# AE302F40C1537LE_CM55_HP_View register map
Vendor: Alif Semiconductor; Series: E3; File version: 1.0
CPU: CM55 r1p0, selectable endian, MPU, FPU, double-precision FPU, DSP, VTOR, 8 interrupt priority bits, 1 SAU regions
Registers are 32-bit, read-write, reset 0x0 unless marked. A register's access mark holds for its fields unless they carry their own. Offsets are from the block's base; [hi:lo] are bit positions; 'fields as' and 'values as' point back to an identical list.

## I2C0
Base 0x49010000
Same registers: I2C1 0x49011000, I2C2 0x49012000, I2C3 0x49013000
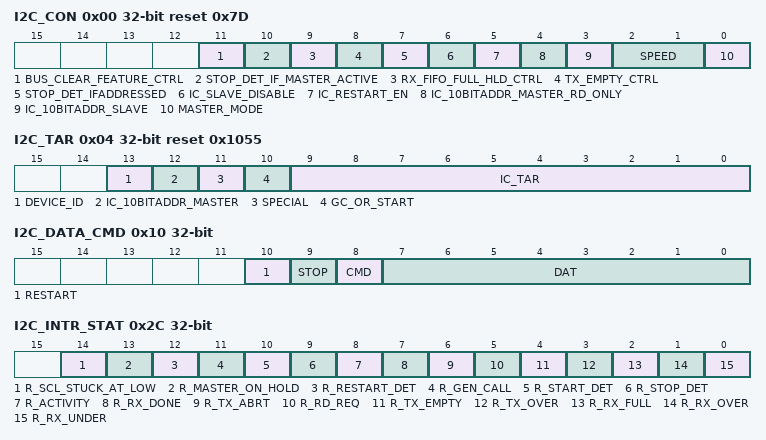
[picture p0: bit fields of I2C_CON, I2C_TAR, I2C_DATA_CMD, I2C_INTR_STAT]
0x00 I2C_CON reset 0x7D — Control Register
  [11] BUS_CLEAR_FEATURE_CTRL — In Master mode: In Slave mode this bit is not applicable.
    0=Bus Clear Feature is disabled; 1=Bus Clear Feature is enabled
  [10] STOP_DET_IF_MASTER_ACTIVE ro — In Master mode:
    0=Master issues the STOP_DET interrupt irrespective of whether master is active or not; 1=Master issues the STOP_DET interrupt only when master is active
  [9] RX_FIFO_FULL_HLD_CTRL ro — This bit controls whether I2C should hold the bus when the Rx FIFO is physically full to its IC_COMP_PARAM_1[RX_BUFFER_DEPTH].
    0=Overflow when RX_FIFO is full; 1=Hold bus when RX_FIFO is full
  [8] TX_EMPTY_CTRL — This bit controls the generation of the TX_EMPTY interrupt, as described in the I2C_RAW_INTR_STAT[TX_EMPTY].
    0=Default behaviour of TX_EMPTY interrupt; 1=Controlled generation of TX_EMPTY interrupt
  [7] STOP_DET_IFADDRESSED — In Slave mode: During a general call address, this slave does not issue the STOP_DET interrupt if STOP_DET_IF_ADDRESSED = 0x1, even if the slave responds to the general call address by generating ACK. The STOP_DET interrupt is generated only when the transmitted address matches the slave address.
    0=Issues the STOP_DET irrespective of whether it is addressed or not; 1=Issues the STOP_DET interrrupt only when it is addressed
  [6] IC_SLAVE_DISABLE — This bit controls whether I2C has its slave disabled. If this bit is set, the Slave mode is disabled, and I2C functions only as a master; it does not perform any action that requires a slave. Software should ensure that if this bit is set to 0, then bit MASTER_MODE should also be set to 0.
    0=Slave mode is enabled; 1=Slave mode is disabled
  [5] IC_RESTART_EN — Determines whether RESTART conditions may be sent when acting as a master. Some older slaves do not support handling RESTART conditions; however, RESTART conditions are used in several I2C operations. When RESTART is disabled, the master is prohibited from performing the following functions: - Sending a START BYTE - Performing any high-speed mode operation - Performing direction changes in combined format mode - Performing a read operation with a 10-bit address
    0=Master restart disabled; 1=Master restart enabled
  [4] IC_10BITADDR_MASTER_RD_ONLY ro — The function of this bit is handled by I2C_TAR[IC_10BITADDR_MASTER] bit, and it is read only.
    0=Master 7-bit addressing mode; 1=Master 10-bit addressing mode
  [3] IC_10BITADDR_SLAVE — When acting as a slave, this bit controls whether the I2C responds to 7-bit or 10-bit addresses. 0x0: 7-bit addressing. The I2C ignores transactions that involve 10-bit addressing; for 7-bit addressing, only the lower 7 bits of the I2C_SAR register are compared. 0x1: 10-bit addressing. The I2C responds to only 10-bit addressing transfers that match the full 10 bits of the I2C_SAR register. 0x0: Slave 7-bit addressing 0x1: Slave 10-bit addressing
  [2:1] SPEED — These bits control at which speed the I2C operates; its setting is relevant only if the I2C operates in Master mode. Hardware protects against illegal values being programmed by software. These bits must be programmed appropriately for Slave mode also, as they are used to capture correct value of spike filter as per the speed mode. This register should be programmed only with a value in the range of 1 to 2.
    1=Standard mode of operation; 2=Fast or Fast Plus mode of operation
  [0] MASTER_MODE — This bit controls whether the I2C master is enabled. NOTE: Software should ensure that if this bit is set to 1, bit IC_SLAVE_DISABLE should also be set to 1.
    0=Master mode is disabled; 1=Master mode is enabled
0x04 I2C_TAR reset 0x1055 — Target Address Register
  [13] DEVICE_ID — If bit SPECIAL is set to 1, then this bit indicates whether a Device-ID of a particular slave mentioned in I2C_TAR[IC_TAR] is to be performed by the I2C Master.
    0=Disables programming of DEVICE-ID transmission. Device-ID is not performed and checks I2C_TAR[GC_OR_START] to perform either general call or START byte command.; 1=Enables programming of DEVICE-ID transmission. Device-ID transfer is performed and bytes based on the number of read commands in the Tx FIFO are received from the targeted slave and put in the Rx FIFO.
  [12] IC_10BITADDR_MASTER — This bit controls whether the I2C starts its transfers in 7-bit or 10-bit addressing mode when acting as a master.
    0=7-bit addressing mode; 1=10-bit addressing mode
  [11] SPECIAL — This bit indicates whether software performs a DEVICE_ID or General Call or START BYTE command.
    0=Disables programming of GENERAL_CALL or START_BYTE transmission. Ignore GC_OR_START bit and use I2C_TAR normally.; 1=Enables programming of GENERAL_CALL or START_BYTE transmission. Perform special I2C command as specified in Device_ID or GC_OR_START bit.
  [10] GC_OR_START — If bit SPECIAL is set to 1 and bit DEVICE_ID is set to 0, then this bit indicates whether a General Call or START byte command is performed by the I2C. General Call Address-after issuing a General Call, only writes may be performed. Attempting to issue a read command results in setting I2C_RAW_INTR_STAT[TX_ABRT] bit. The I2C remains in General Call mode until the SPECIAL bit value is cleared.
    0=GENERAL_CALL byte transmission; 1=START BYTE transmission
  [9:0] IC_TAR — This is the target address for any master transaction. When transmitting a General Call, these bits are ignored. To generate a START_BYTE command, the CPU needs to write only once into these bits. If the I2C_TAR and I2C_SAR[IC_SAR] are the same, loopback exists but the FIFOs are shared between master and slave, so full loopback is not feasible. Only one direction loopback mode is supported (simplex), not duplex. A master can not transmit to itself; it can transmit to only a slave.
0x08 I2C_SAR reset 0x55 — Slave Address Register
  [9:0] IC_SAR — The I2C_SAR holds the slave address when the I2C is operating as a slave. For 7-bit addressing, the I2C_SAR[IC_SAR] bit field is [6-0]. This field is written only when the I2C interface is disabled, which corresponds to the I2C_ENABLE[ENABLE] bit set to 0x0. Writes at other times have no effect.
0x10 I2C_DATA_CMD — Rx/Tx Data Buffer and Command Register
  [10] RESTART wo — This bit controls whether a RESTART condition is issued before the byte is sent or received.
    0=If I2C_CON[IC_RESTART_EN] bit is 1, a RESTART is issued only if the transfer direction is changing from the previous command; if IC_RESTART_EN is 0, a STOP followed by a START is issued instead; 1=If I2C_CON[IC_RESTART_EN] bit is 1, a RESTART is issued before the data is sent/received (according to the value of bit CMD), regardless of whether or not the transfer direction is changing from the previous command; if IC_RESTART_EN is 0, a STOP followed by a START is issued instead
  [9] STOP wo — This bit controls whether a STOP condition is issued after the byte is sent or received.
    0=STOP is not issued after this byte, regardless of whether or not the Tx FIFO is empty. If the Tx FIFO is not empty, the master continues the current transfer by sending/receiving data bytes according to the value of the CMD bit. If the Tx FIFO is empty, the master holds the SCL line low and stalls the bus until a new command is available in the Tx FIFO; 1=STOP is issued after this byte, regardless of whether or not the Tx FIFO is empty. If the Tx FIFO is not empty, the master immediately tries to start a new transfer by issuing a START and arbitrating for the bus.
  [8] CMD wo — This bit controls whether a read or a write is performed. This bit does not control the direction when the I2C acts as a slave. It controls only the direction when it acts as a master. When a command is entered in the Tx FIFO, this bit distinguishes the write and read commands. In slave-receiver mode, this bit is a 'don't care' because writes to this register are not required. In slave-transmitter mode, a 0 indicates that the data in I2C_DATA_CMD[DAT] bit is to be transmitted. When this bit is programmed attempting to perform a read operation after a General Call command has been sent results in a TX_ABRT interrupt (I2C_RAW_INTR_STAT[TX_ABRT] bit), unless the I2C_TAR[SPECIAL] bit has been cleared. If a 1 is written to this bit after receiving a RD_REQ interrupt, then a TX_ABRT interrupt occurs.
    0=Master write command; 1=Master read command
  [7:0] DAT — This field contains the data to be transmitted or received on the I2C bus. If a write to this register is performed and a read is needed, field DAT is ignored by the I2C. If a read is preformed, these bits return the value of data received on the I2C interface.
0x14 I2C_SS_SCL_HCNT reset 0x190 — Standard Speed SCL High Count Register
  [15:0] IC_SS_SCL_HCNT — This field must be set before any I2C bus transaction can take place to ensure proper I/O timing. It sets the SCL clock high-period count for Standard Speed. This field is written only when the I2C interface is disabled which corresponds to the I2C_ENABLE[ENABLE] bit is set to 0x0. Writes at other times have no effect. The minimum valid value is 6; hardware prevents values less than this being written, and if attempted results in 6 being set. Note: This field must not be programmed to a value higher than 65525, because I2C uses a 16-bit counter to flag an I2C bus IDLE condition when this counter reaches a value of I2C_SS_SCL_HCNT + 10.
0x18 I2C_SS_SCL_LCNT reset 0x1D6 — Standard Speed SCL Low Count Register
  [15:0] IC_SS_SCL_LCNT — This field must be set before any I2C bus transaction can take place to ensure proper I/O timing. This register sets the SCL clock low period count for Standard Speed. This field is written only when the I2C interface is disabled which corresponds to the I2C_ENABLE[ENABLE] bit is set to 0x0. Writes at other times have no effect. The minimum valid value is 8; Hardware prevents values less than this being written, and if attempted, results in 8 being set.
0x1C I2C_FS_SCL_HCNT reset 0x3C — Fast Mode or Fast Mode Plus SCL High Count Register
  [15:0] IC_FS_SCL_HCNT — This register must be set before any I2C bus transaction can take place to ensure proper I/O timing. This register sets the SCL clock high-period count for Fast mode or Fast mode plus. This register is written only when the I2C interface is disabled, which corresponds to the I2C_ENABLE[ENABLE] bit is set to 0x0. Writes at other times have no effect. The minimum valid value is 6; Hardware prevents values less than this being written, and if attempted results in 6 being set.
0x20 I2C_FS_SCL_LCNT reset 0x82 — Fast Mode or Fast Mode Plus SCL Low Count Register
  [15:0] IC_FS_SCL_LCNT — This register must be set before any I2C bus transaction can take place to ensure proper I/O timing. This register sets the SCL clock low period count for Fast-Speed. This register is written only when the I2C interface is disabled, which corresponds to the I2C_ENABLE[ENABLE] bit is set to 0x0. Writes at other times have no effect. The minimum valid value is 8; Hardware prevents values less than this being written, and if attempted results in 8 being set.
0x2C I2C_INTR_STAT ro — Interrupt Status Register
  [14] R_SCL_STUCK_AT_LOW — See also I2C_RAW_INTR_STAT[SCL_STUCK_AT_LOW]
    0=R_SCL_STUCK_AT_LOW interrupt is inactive; 1=R_SCL_STUCK_AT_LOW interrupt is active
  [13] R_MASTER_ON_HOLD — See also I2C_RAW_INTR_STAT[MASTER_ON_HOLD]
    0=R_MASTER_ON_HOLD interrupt is inactive; 1=R_MASTER_ON_HOLD interrupt is active
  [12] R_RESTART_DET — See also I2C_RAW_INTR_STAT[RESTART_DET]
    0=R_RESTART_DET interrupt is inactive; 1=R_RESTART_DET interrupt is active
  [11] R_GEN_CALL — See also I2C_RAW_INTR_STAT[GEN_CALL]
    0=R_GEN_CALL interrupt is inactive; 1=R_GEN_CALL interrupt is active
  [10] R_START_DET — See also I2C_RAW_INTR_STAT[START_DET]
    0=R_START_DET interrupt is inactive; 1=R_START_DET interrupt is active
  [9] R_STOP_DET — See also I2C_RAW_INTR_STAT[STOP_DET]
    0=R_STOP_DET interrupt is inactive; 1=R_STOP_DET interrupt is active
  [8] R_ACTIVITY — See also I2C_RAW_INTR_STAT[ACTIVITY]
    0=R_ACTIVITY interrupt is inactive; 1=R_ACTIVITY interrupt is active
  [7] R_RX_DONE — See also I2C_RAW_INTR_STAT[RX_DONE]
    0=R_RX_DONE interrupt is inactive; 1=R_RX_DONE interrupt is active
  [6] R_TX_ABRT — See also I2C_RAW_INTR_STAT[TX_ABRT]
    0=R_TX_ABRT interrupt is inactive; 1=R_TX_ABRT interrupt is active
  [5] R_RD_REQ — See also I2C_RAW_INTR_STAT[RD_REQ]
    0=R_RD_REQ interrupt is inactive; 1=R_RD_REQ interrupt is active
  [4] R_TX_EMPTY — See also I2C_RAW_INTR_STAT[TX_EMPTY]
    0=R_TX_EMPTY interrupt is inactive; 1=R_TX_EMPTY interrupt is active
  [3] R_TX_OVER — See also I2C_RAW_INTR_STAT[TX_OVER]
    0=R_TX_OVER interrupt is inactive; 1=R_TX_OVER interrupt is active
  [2] R_RX_FULL — See also I2C_RAW_INTR_STAT[RX_FULL]
    0=R_RX_FULL interrupt is inactive; 1=R_RX_FULL interrupt is active
  [1] R_RX_OVER — See also I2C_RAW_INTR_STAT[RX_OVER]
    0=R_RX_OVER interrupt is inactive; 1=R_RX_OVER interrupt is active
  [0] R_RX_UNDER — See also I2C_RAW_INTR_STAT[RX_UNDER]
    0=R_RX_UNDER interrupt is inactive; 1=R_RX_UNDER interrupt is active
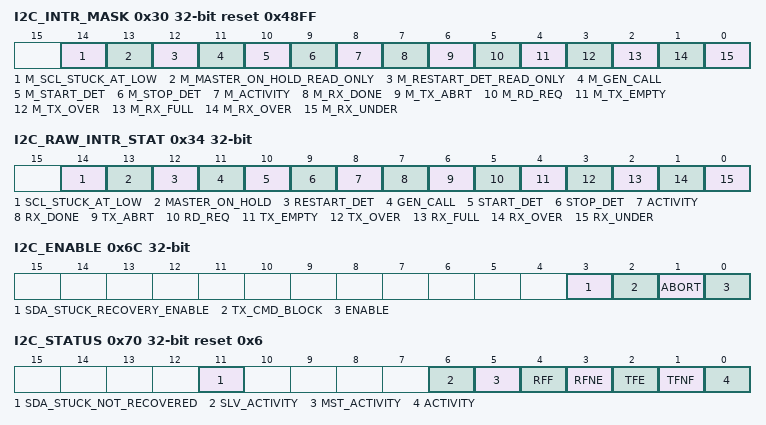
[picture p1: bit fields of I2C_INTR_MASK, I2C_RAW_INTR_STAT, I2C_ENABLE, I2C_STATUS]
0x30 I2C_INTR_MASK reset 0x48FF — Interrupt Mask Register
  [14] M_SCL_STUCK_AT_LOW — This bit masks the R_SCL_STUCK_AT_LOW interrupt in I2C_INTR_STAT register.
    0=SCL_STUCK_AT_LOW interrupt is masked; 1=SCL_STUCK_AT_LOW interrupt is unmasked
  [13] M_MASTER_ON_HOLD_READ_ONLY ro — This bit masks the M_MASTER_ON_HOLD_READ_ONLY interrupt in I2C_INTR_STAT register.
    0=MASTER_ON_HOLD interrupt is masked; 1=MASTER_ON_HOLD interrupt is unmasked
  [12] M_RESTART_DET_READ_ONLY ro — This bit masks the M_RESTART_DET_READ_ONLY interrupt in I2C_INTR_STAT register.
    0=RESTART_DET interrupt is masked; 1=RESTART_DET interrupt is unmasked
  [11] M_GEN_CALL — This bit masks the R_GEN_CALL interrupt in I2C_INTR_STAT register.
    0=GEN_CALL interrupt is masked; 1=GEN_CALL interrupt is unmasked
  [10] M_START_DET — This bit masks the R_START_DET interrupt in I2C_INTR_STAT register.
    0=START_DET interrupt is masked; 1=START_DET interrupt is unmasked
  [9] M_STOP_DET — This bit masks the R_STOP_DET interrupt in I2C_INTR_STAT register.
    0=STOP_DET interrupt is masked; 1=STOP_DET interrupt is unmasked
  [8] M_ACTIVITY — This bit masks the R_ACTIVITY interrupt in I2C_INTR_STAT register.
    0=ACTIVITY interrupt is masked; 1=ACTIVITY interrupt is unmasked
  [7] M_RX_DONE — This bit masks the R_RX_DONE interrupt in I2C_INTR_STAT register.
    0=RX_DONE interrupt is masked; 1=RX_DONE interrupt is unmasked
  [6] M_TX_ABRT — This bit masks the R_TX_ABRT interrupt in I2C_INTR_STAT register.
    0=TX_ABORT interrupt is masked; 1=TX_ABORT interrupt is unmasked
  [5] M_RD_REQ — This bit masks the R_RD_REQ interrupt in I2C_INTR_STAT register.
    0=RD_REQ interrupt is masked; 1=RD_REQ interrupt is unmasked
  [4] M_TX_EMPTY — This bit masks the R_TX_EMPTY interrupt in I2C_INTR_STAT register.
    0=TX_EMPTY interrupt is masked; 1=TX_EMPTY interrupt is unmasked
  [3] M_TX_OVER — This bit masks the R_TX_OVER interrupt in I2C_INTR_STAT register.
    0=TX_OVER interrupt is masked; 1=TX_OVER interrupt is unmasked
  [2] M_RX_FULL — This bit masks the R_RX_FULL interrupt in I2C_INTR_STAT register.
    0=RX_FULL interrupt is masked; 1=RX_FULL interrupt is unmasked
  [1] M_RX_OVER — This bit masks the R_RX_OVER interrupt in I2C_INTR_STAT register.
    0=RX_OVER interrupt is masked; 1=RX_OVER interrupt is unmasked
  [0] M_RX_UNDER — This bit masks the R_RX_UNDER interrupt in I2C_INTR_STAT register.
    0=RX_UNDER interrupt is masked; 1=RX_UNDER interrupt is unmasked
0x34 I2C_RAW_INTR_STAT ro — Raw Interrupt Status Register
  [14] SCL_STUCK_AT_LOW — Indicates whether the SCL Line is stuck at low for the IC_SCL_STUCK_LOW_TIMEOUT number of IC_CLK periods.
    0=SCL_STUCK_AT_LOW interrupt is inactive; 1=SCL_STUCK_AT_LOW interrupt is active
  [13] MASTER_ON_HOLD — Indicates whether master is holding the bus and TX FIFO is empty.
    0=MASTER_ON_HOLD interrupt is inactive; 1=MASTER_ON_HOLD interrupt is active
  [12] RESTART_DET — Indicates whether a RESTART condition has occurred on the I^2C interface when I2C is operating in Slave mode and the slave is being addressed. During a Start Byte transfer, the RESTART comes before the address field as per the I^2C protocol. In this case, the slave is not the addressed slave when the RESTART is issued, therefore I2C does not generate the RESTART_DET interrupt.
    0=RESTART_DET interrupt is inactive; 1=RESTART_DET interrupt is active
  [11] GEN_CALL — Set only when a General Call address is received and it is acknowledged. It stays set until it is cleared either by disabling I2C or when the CPU reads bit 0 of the I2C_CLR_GEN_CALL register. I2C stores the received data in the Rx buffer.
    0=GEN_CALL interrupt is inactive; 1=GEN_CALL interrupt is active
  [10] START_DET — Indicates whether a START or RESTART condition has occurred on the I2C interface regardless of whether I2C is operating in Slave or Master mode.
    0=START_DET interrupt is inactive; 1=START_DET interrupt is active
  [9] STOP_DET — Indicates whether a STOP condition has occurred on the I^2C interface regardless of whether I2C is operating in Slave or Master mode. In Slave mode: If I2C_CON[STOP_DET_IFADDRESSED] is set to 0x1 , the STOP_DET interrupt will be issued only if slave is addressed. Note: During a general call address, this slave does not issue a STOP_DET interrupt if I2C_CON[STOP_DET_IFADDRESSED] is set to 0x1, even if the slave responds to the general call address by generating ACK. The STOP_DET interrupt is generated only when the transmitted address matches the slave address (SAR). If I2C_CON[STOP_DET_IFADDRESSED] is set to 0x0, the STOP_DET interrupt is issued irrespective of whether it is being addressed. In Master mode: If I2C_CON[STOP_DET_IF_MASTER_ACTIVE] is set to 0x1, the STOP_DET interrupt will be issued only if master is active. If I2C_CON[STOP_DET_IF_MASTER_ACTIVE] is set to 0x0, the STOP_DET interrupt will be issued irrespective of whether master is active or not.
    0=STOP_DET interrupt is inactive; 1=STOP_DET interrupt is active
  [8] ACTIVITY — This bit captures I2C activity and stays set until it is cleared. There are four ways to clear it: - Disabling the I2C - Reading the I2C_CLR_ACTIVITY register - Reading the I2C_CLR_INTR register - System reset
    0=RAW_INTR_ACTIVITY interrupt is inactive; 1=RAW_INTR_ACTIVITY interrupt is active
  [7] RX_DONE — When the I2C is acting as a slave-transmitter, this bit is set to 1 if the master does not acknowledge a transmitted byte. This occurs on the last byte of the transmission, indicating that the transmission is done.
    0=RX_DONE interrupt is inactive; 1=RX_DONE interrupt is active
  [6] TX_ABRT — This bit indicates if I2C, as an I2C transmitter, is unable to complete the intended actions on the contents of theTx FIFO. This situation can occur both as an I2C master or an I2C slave, and is referred to as a transmit abort. When this bit is set to 0x1, the I2C_TX_ABRT_SOURCE register indicates the reason why the transmit abort takes places. The I2C flushes/resets/empties only the TX_FIFO whenever there is a transmit abort caused by any of the events tracked by the I2C_TX_ABRT_SOURCE register. The Tx FIFO remains in this flushed state until the I2C_CLR_TX_ABRT register is read. Once this read is performed, theTx FIFO is then ready to accept more data bytes from the APB interface.
    0=TX_ABRT interrupt is inactive; 1=TX_ABRT interrupt is active
  [5] RD_REQ — This bit is set to 0x1 when I2C is acting as a slave and another I2C master is attempting to read data from I2C. The I2C holds the I2C bus in a wait state until this interrupt is serviced, which means that the slave has been addressed by a remote master that is asking for data to be transferred. The processor must respond to this interrupt and then write there quested data to the I2C_DATA_CMD register. This bit is set to 0 just after the processor reads the I2C_CLR_RD_REQ register.
    0=RD_REQ interrupt is inactive; 1=RD_REQ interrupt is active
  [4] TX_EMPTY — The behavior of the TX_EMPTY interrupt status differs based on the selection in the I2C_CON[TX_EMPTY_CTRL] bit. When TX_EMPTY_CTRL is set to 0x0: This bit is set to 1 when the transmit buffer is at or below the threshold value set in the I2C_TX_TL register. When TX_EMPTY_CTRL is set to 0x1: This bit is set to 1 when the transmit buffer is at or below the threshold value set in the I2C_TX_TL register and the transmission of the address/data from the internal shift register for the most recently popped command is completed.
    0=TX_EMPTY interrupt is inactive; 1=TX_EMPTY interrupt is active
  [3] TX_OVER — Set during transmit if the transmit buffer is filled to 32 and the processor attempts to issue another I2C command by writing to the I2C_DATA_CMD register. When the module is disabled, this bit keeps its level until the master or slave state machines go into IDLE, and when I2C_ENABLE[ENABLE] goes to 0x0, this interrupt is cleared.
    0=TX_OVER interrupt is inactive; 1=TX_OVER interrupt is active
  [2] RX_FULL — Set when the receive buffer reaches or goes above the RX_TL threshold in the I2C_RX_TL register. It is automatically cleared by hardware when buffer level goes below the threshold. If the module is disabled (I2C_ENABLE[ENABLE] is set to 0x0), the Rx FIFO is flushed and held in reset; therefore the Rx FIFO is not full. So, this bit is cleared once the I2C_ENABLE[ENABLE] bit is set to 0x0, regardless of the activity that continues.
    0=RX_FULL interrupt is inactive; 1=RX_FULL interrupt is active
  [1] RX_OVER — Set if the receive buffer is completely filled to 32 and an additional byte is received from an external I2C device. The I2C acknowledges this, but any data bytes received after the FIFO is full are lost. If the module is disabled (I2C_ENABLE[ENABLE] is set ot 0x0), this bit keeps its level until the master or slave state machines go into IDLE, and when I2C_ENABLE[ENABLE] is set ot 0x0, this interrupt is cleared.
    0=RX_OVER interrupt is inactive; 1=RX_OVER interrupt is active
  [0] RX_UNDER — Set if the processor attempts to read the receive buffer when it is empty by reading from the I2C_DATA_CMD register. If the module is disabled(I2C_ENABLE[ENABLE] is set ot 0x0), this bit keeps its level until the master or slave state machines go into IDLE, and when I2C_ENABLE[ENABLE] is set ot 0x0, this interrupt is cleared.
    0=RX_UNDER interrupt is inactive; 1=RX_UNDER interrupt is active
0x38 I2C_RX_TL — Receive FIFO Threshold Register
  [7:0] RX_TL — Controls the level of entries (or above) that triggers the RX_FULL interrupt (I2C_RAW_INTR_STAT[RX_FULL] bit). The valid range is 0-255, with the additional restriction that hardware does not allow this value to be set to a value larger than the depth of the buffer. If an attempt is made to do that, the actual value set will be the maximum depth of the buffer. A value of 0 sets the threshold for 1 entry, and a value of 255 sets the threshold for 256 entries.
0x3C I2C_TX_TL — Transmit FIFO Threshold Register
  [7:0] TX_TL — Controls the level of entries (or below) that triggers the TX_EMPTY interrupt (I2C_RAW_INTR_STAT[TX_EMPTY] bit). The valid range is 0-255, with the additional restriction that it may not be set to value larger than the depth of the buffer. If an attempt is made to do that, the actual value set will be the maximum depth of the buffer. A value of 0 sets the threshold for 0 entries, and a value of 255 sets the threshold for 255 entries.
0x40 I2C_CLR_INTR ro — Clear Combined and Individual Interrupt Register
  [0] CLR_INTR — Read this bit to: - Clear the combined interrupt; - Clear all individual interrupts; - Clear the I2C_TX_ABRT_SOURCE register; This bit does not clear hardware clearable interrupts. Refer to the I2C_TX_ABRT_SOURCE[ABRT_SBYTE_NORSTRT] bit for an exception to clearing it.
0x44 I2C_CLR_RX_UNDER ro — Clear RX_UNDER Interrupt Register
  [0] CLR_RX_UNDER — Read this bit to clear the I2C_RAW_INTR_STAT[RX_UNDER] bit.
0x48 I2C_CLR_RX_OVER ro — Clear RX_OVER Interrupt Register
  [0] CLR_RX_OVER — Read this bit to clear the I2C_RAW_INTR_STAT[RX_OVER] bit.
0x4C I2C_CLR_TX_OVER ro — Clear TX_OVER Interrupt Register
  [0] CLR_TX_OVER — Read this bit to clear the I2C_RAW_INTR_STAT[TX_OVER] bit.
0x50 I2C_CLR_RD_REQ ro — Clear RD_REQ Interrupt Register
  [0] CLR_RD_REQ — Read this bit to clear the I2C_RAW_INTR_STAT[RD_REQ] bit.
0x54 I2C_CLR_TX_ABRT ro — Clear TX_ABRT Interrupt Register
  [0] CLR_TX_ABRT — Read this bit to clear the I2C_RAW_INTR_STAT[TX_ABRT] bit, and the I2C_TX_ABRT_SOURCE register. This also releases the Tx FIFO from the flushed/reset state, allowing more writes to the Tx FIFO. Refer to I2C_TX_ABRT_SOURCE[ABRT_SBYTE_NORSTRT] bit for an exception to clearing it.
0x58 I2C_CLR_RX_DONE ro — Clear RX_DONE Interrupt Register
  [0] CLR_RX_DONE — Read this bit to clear the I2C_RAW_INTR_STAT[RX_DONE] bit.
0x5C I2C_CLR_ACTIVITY ro — Clear ACTIVITY Interrupt Register
  [0] CLR_ACTIVITY — Reading this bit clears the ACTIVITY interrupt if the I2C is not active anymore. If the I2C module is still active on the bus, the ACTIVITY interrupt bit continues to be set. It is automatically cleared by hardware if the module is disabled and if there is no further activity on the bus. The value read from this bit give status of the I2C_RAW_INTR_STAT[ACTIVITY] bit.
0x60 I2C_CLR_STOP_DET ro — Clear STOP_DET Interrupt Register
  [0] CLR_STOP_DET — Read this bit to clear the I2C_RAW_INTR_STAT[STOP_DET] bit.
0x64 I2C_CLR_START_DET ro — Clear START_DET Interrupt Register
  [0] CLR_START_DET — Read this bit to clear the I2C_RAW_INTR_STAT[START_DET] bit.
0x68 I2C_CLR_GEN_CALL ro — Clear GEN_CALL Interrupt Register
  [0] CLR_GEN_CALL — Read this bit to clear the I2C_RAW_INTR_STAT[GEN_CALL] bit.
0x6C I2C_ENABLE — Enable Register
  [3] SDA_STUCK_RECOVERY_ENABLE — If SDA is stuck at low indicated through the TX_ABORT interrupt(I2C_TX_ABRT_SOURCE[TX_ABORT] bit), then this bit is used as a control knob to initiate the SDA recovery mechanism (that is, send at most 9 SCL clocks and STOP to release the SDA line) and then this bit gets auto clear.
    0=Master disables the SDA stuck at low recovery mechanism; 1=Master initates the SDA stuck at low recovery mechanism
  [2] TX_CMD_BLOCK — In Master mode: To block the execution of master commands, set the TX_CMD_BLOCK bit only when Tx FIFO is empty (I2C_STATUS[TFE] set to 0x1) and master is in IDLE state (I2C_STATUS[MST_ACTIVITY] is set to 0). Any further commands put in the Tx FIFO are not executed until TX_CMD_BLOCK bit is unset.
    0=Tx Command execution not blocked. The transmission of data starts on I2C bus automatically, as soon as the first data is available in the Tx FIFO.; 1=Tx Command execution blocked. Blocks the transmission of data on I2C bus even if Tx FIFO has data to transmit.
  [1] ABORT — When set, the controller initiates the transfer abort.
    0=ABORT operation not in progress; 1=ABORT operation in progress
  [0] ENABLE — Controls whether the I2C is enabled. When I2C is disabled, the following occurs: - The Tx FIFO and Rx FIFO get flushed. - Status bits in the I2C_INTR_STAT register are still active until I2C goes into IDLE state.
    0=Disables I2C (Tx and Rx FIFOs are held in an erased state); 1=Enables I2C
0x70 I2C_STATUS ro reset 0x6 — Status Register
  [11] SDA_STUCK_NOT_RECOVERED — This bit indicates that SDA stuck at low is not recovered after the recovery mechanism. In Slave mode, this register bit is not applicable.
    0=SDA Stuck at low is not recovered after recovery mechanism; 1=SDA Stuck at low is recovered after recovery mechanism
  [6] SLV_ACTIVITY — Slave Finite State Machine (FSM) Activity Status. When the Slave is not in the IDLE state, this bit is set.
    0=Slave FSM is in IDLE state-the slave part of I2C is not Active; 1=Slave FSM is not in IDLE state-the slave part of I2C is Active
  [5] MST_ACTIVITY — Master FSM Activity Status. When the Master is not in the IDLE state, this bit is set. Note: I2C_STATUS[ACTIVITY] bit is an OR of SLV_ACTIVITY and MST_ACTIVITY bits.
    0=Master FSM is in IDLE state-the master part of I2C is not Active; 1=Master FSM is not in IDLE state-the master part of I2C is Active
  [4] RFF — Receive FIFO Completely Full. When the receive FIFO is completely full, this bit is set. When the receive FIFO contains one or more empty location, this bit is cleared.
    0=Rx FIFO not full; 1=Rx FIFO is full
  [3] RFNE — Receive FIFO Not Empty. This bit is set when the receive FIFO contains one or more entries; it is cleared when the receive FIFO is empty.
    0=Rx FIFO is empty; 1=Rx FIFO not empty
  [2] TFE — Transmit FIFO Completely Empty. When the transmit FIFO is completely empty, this bit is set. When it contains one or more valid entries, this bit iscleared. This bit does not request an interrupt.
    0=Tx FIFO not empty; 1=Tx FIFO is empty
  [1] TFNF — Transmit FIFO Not Full. Set when the transmit FIFO contains one or more empty locations, and is cleared when the FIFO is full.
    0=Tx FIFO is full; 1=Tx FIFO not full
  [0] ACTIVITY — I2C Activity Status
    0=I2C is IDLE; 1=I2C is active
0x74 I2C_TXFLR ro — Transmit FIFO Level Register
  [5:0] TXFLR — Tx FIFO Level Contains the number of valid data entries in the Tx FIFO.
0x78 I2C_RXFLR ro — Receive FIFO Level Register
  [5:0] RXFLR — Rx FIFO Level. Contains the number of valid data entries in the Rx FIFO.
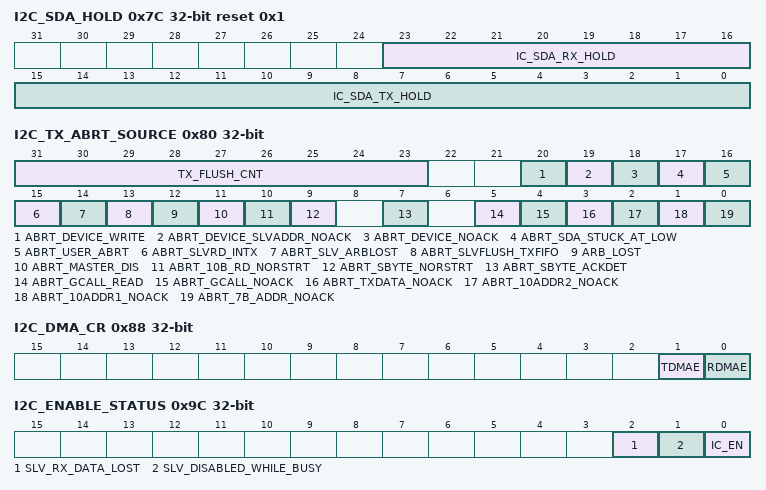
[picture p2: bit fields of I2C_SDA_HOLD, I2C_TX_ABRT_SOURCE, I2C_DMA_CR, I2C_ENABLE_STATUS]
0x7C I2C_SDA_HOLD reset 0x1 — SDA Hold Time Length Register
  [23:16] IC_SDA_RX_HOLD — Sets the required SDA hold time in units of IC_CLK period, when I2C acts as a receiver.
  [15:0] IC_SDA_TX_HOLD — Sets the required SDA hold time in units of IC_CLK period, when I2C acts as a transmitter.
0x80 I2C_TX_ABRT_SOURCE ro — Transmit Abort Source Register
  [31:23] TX_FLUSH_CNT — This field indicates the number of Tx FIFO data commands which are flushed due to TX_ABRT interrupt. It is cleared whenever I2C is disabled. Role of I2C: Master-Transmitter or Slave-Transmitter
  [20] ABRT_DEVICE_WRITE — This is a master-mode-only bit. Master is initiating the DEVICE_ID transfer and the Tx FIFO consists of write commands. Role of I2C: Master
    0=This abort is not generated; 1=This abort is generated because of NOACK for slave address
  [19] ABRT_DEVICE_SLVADDR_NOACK — This is a master-mode-only bit. Master is initiating the DEVICE_ID transfer and the slave address sent was not acknowledged by any slave. Role of I2C: Master
    values as ABRT_DEVICE_WRITE
  [18] ABRT_DEVICE_NOACK — This is a master-mode-only bit. Master is initiating the DEVICE_ID transfer and the device id sent was not acknowledged by any slave. Role of I2C: Master
    0=This abort is not generated; 1=This abort is generated because of NOACK for DEVICE-ID
  [17] ABRT_SDA_STUCK_AT_LOW — This is a master-mode-only bit. Master detects the SDA stuck at low for the IC_CLK. Role of I2C: Master
    0=This abort is not generated; 1=This abort is generated because of SDA stuck at low for the IC_CLK
  [16] ABRT_USER_ABRT — This is a master-mode-only bit. Master has detected the transfer abort (I2C_ENABLE[ABORT] bit). Role of I2C: Master-Transmitter
    0=Transfer abort detected by master-scenario not present; 1=Transfer abort detected by master
  [15] ABRT_SLVRD_INTX — When the processor side responds to a Slave mode request for data to be transmitted to a remote master and I2C_DATA_CMD[CMD] bit is set to 0x1. Role of I2C: Slave-Transmitter
    0=Slave trying to transmit to remote master in read mode- scenario not present; 1=Slave trying to transmit to remote master in read mode
  [14] ABRT_SLV_ARBLOST — This field indicates that a slave has lost the bus while transmitting data to a remote master. The I2C_TX_ABRT_SOURCE[ARB_LOST] is set at the same time. Even though the slave never owns the bus, something could go wrong on the bus. This is a fail safe check. For instance, during a data transmission at the low-to-high transition of SCL, if what is on the data bus is not what is supposed to be transmitted, then I2C no longer own the bus. Role of I2C: Slave-Transmitter
    0=Slave lost arbitration to remote master- scenario not present; 1=Slave lost arbitration to remote master
  [13] ABRT_SLVFLUSH_TXFIFO — This field specifies that the slave has received a read command and some data exists in the Tx FIFO, so the slave issues a TX_ABRT interrupt to flush old data in Tx FIFO. Role of I2C: Slave-Transmitter
    0=Slave flushes existing data in Tx FIFO upon getting read command- scenario not present; 1=Slave flushes existing data in Tx FIFO upon getting read command
  [12] ARB_LOST — This field specifies that the master has lost arbitration, or if I2C_TX_ABRT_SOURCE[ABRT_SLV_ARBLOST] is also set, then the slave transmitter has lost arbitration. Role of I2C: Master-Transmitter or Slave-Transmitter
    0=Master or Slave-Transmitter lost arbitration- scenario not present; 1=Master or Slave-Transmitter lost arbitration
  [11] ABRT_MASTER_DIS — This field indicates the master operation with the Master mode disabled. Role of I2C: Master-Transmitter or Master-Receiver
    0=Initiate master operation when Master disabled- scenario not present; 1=Intitate master operation when Master disabled
  [10] ABRT_10B_RD_NORSTRT — This field indicates that the restart is disabled (I2C_CON[IC_RESTART_EN] bit set to 0x0) and the master sends a read command in 10-bit addressing mode. Role of I2C: Master-Receiver
    0=Master not read in 10-bit addressing mode when RESTART disabled; 1=Master read in 10-bit addressing mode when RESTART disabled
  [9] ABRT_SBYTE_NORSTRT — To clear the ABRT_SBYTE_NORSTRT must be fixed first; - Restart must be enabled (I2C_CON[IC_RESTART_EN] is set to 0x1); - I2C_TAR[SPECIAL] bit must be cleared; - I2C_TAR[GC_OR_START] bit must be cleared; Once the source of the ABRT_SBYTE_NORSTRT is fixed, then this bit is cleared in the same manner as other bits in this register. If the source of the ABRT_SBYTE_NORSTRT is not fixed before attempting to clear this bit, it clears for one cycle and then gets reasserted. When this field is set to 1, the restart is disabled (I2C_CON[IC_RESTART_EN] bit is set to 0x0) and then send a START Byte. Role of I2C: Master
    0=Send START byte when RESTART disabled- scenario not present; 1=Send START byte when RESTART disabled
  [7] ABRT_SBYTE_ACKDET — This field indicates that the master has sent a START byte and the START byte was acknowledged (wrong behavior). Role of I2C: Master
    0=ACK detected for START byte- scenario not present; 1=ACK detected for START byte
  [5] ABRT_GCALL_READ — This field indicates that I2C in the Master mode has sent a General Call but following programmed byte the General Call to be a read from the bus (I2C_DATA_CMD[CMD] is set to 0x1). Role of I2C: Master-Transmitter
    0=GCALL is followed by read from bus-scenario not present; 1=GCALL is followed by read from bus
  [4] ABRT_GCALL_NOACK — This field indicates that I2C in Master mode has sent a General Call and no slave on the bus acknowledged the General Call. Role of I2C: Master-Transmitter
    0=GCALL not acknowledged by any slave-scenario not present; 1=GCALL not acknowledged by any slave
  [3] ABRT_TXDATA_NOACK — This field indicates the master-mode-only bit. When the master receives an acknowledgement for the address, but when it sends data byte(s) following the address, it did not receive an acknowledge from the remote slave(s). Role of I2C: Master-Transmitter
    0=Transmitted data not acknowledged by addressed slave-scenario not present; 1=Transmitted data not acknowledged by addressed slave
  [2] ABRT_10ADDR2_NOACK — This field indicates that the master is in 10-bit address mode and that the second address byte of the 10-bit address was not acknowledged by any slave. Role of I2C: Master-Transmitter or Master-Receiver
    0=This abort is not generated; 1=Byte 2 of 10-bit address not acknowledged by any slave
  [1] ABRT_10ADDR1_NOACK — This field indicates that the master is in 10-bit address mode and the first 10-bit address byte was not acknowledged by any slave. Role of I2C: Master-Transmitter or Master-Receiver
    0=This abort is not generated; 1=Byte 1 of 10-bit address not acknowledged by any slave
  [0] ABRT_7B_ADDR_NOACK — This field indicates that the master is in 7-bit addressing mode and the address sent was not acknowledged by any slave. Role of I2C: Master-Transmitter or Master-Receiver
    0=This abort is not generated; 1=This abort is generated because of NOACK for 7-bit address
0x88 I2C_DMA_CR — DMA Control Register
  [1] TDMAE — Transmit DMA Enable. This bit enables/disables the Tx FIFO DMA channel.
    0=Tx FIFO DMA channel disabled; 1=Tx FIFO DMA channel enabled
  [0] RDMAE — Receive DMA Enable. This bit enables/disables the Rx FIFO DMA channel.
    0=Rx FIFO DMA channel disabled; 1=Rx FIFO DMA channel enabled
0x8C I2C_DMA_TDLR — DMA Transmit Data Level Register
  [4:0] DMATDL — Transmit Data Level. This field controls the level at which a DMA request is made by the transmit logic. It is equal to the watermark level; that is, the I2C_DMA_TX signal is generated when the number of valid data entries in the Tx FIFO is equal to or below this field value, and I2C_DMA_CR[TDMAE] is set to 0x1.
0x90 I2C_DMA_RDLR — DMA Transmit Data Level Register
  [4:0] DMARDL — Receive Data Level. This field controls the level at which a DMA request is made by the receive logic. The watermark level = DMARDL + 1; that is, I2C_DMA_RX is generated when the numberof valid data entries in the Rx FIFO is equal to or more than this field value + 1, and I2C_DMA_CR[RDMAE] is set to 0x1. For instance, when IC_DMA_RDLR[DMARDL] is set to 0x0, then I2C_DMA_RX is asserted when 1 or more data entries are present in the Rx FIFO.
0x94 I2C_SDA_SETUP reset 0x64 — SDA Setup Register
  [7:0] SDA_SETUP — SDA Setup It is recommended that if the required delay is 1000 ns, then for an IC_CLK frequency of 10 MHz, I2C_SDA_SETUP should be programmed to a value of 11. I2C_SDA_SETUP must be programmed with a minimum value of 2.
0x98 I2C_ACK_GENERAL_CALL reset 0x1 — ACK General Call Register
  [0] ACK_GEN_CALL — ACK General Call When set to 1, I2C responds with a ACK when it receives a General Call. Otherwise, I2C responds with a NACK.
    0=Generates NACK for General Call; 1=Generates ACK for a General Call
0x9C I2C_ENABLE_STATUS ro — Enable Status Register
  [2] SLV_RX_DATA_LOST — Slave Received Data Lost. This bit indicates if a Slave-Receiver operation has been aborted with at least one data byte received from an I2C transfer due to the setting I2C_ENABLE[ENABLE] bit from 0x1 to 0x0. When read as 0x1, I2C is deemed to have been actively engaged in an aborted I2C transfer (with matching address) and the data phase of the I2C transfer has been entered, even though a data byte has been responded with a NACK. If the remote I2C master terminates the transfer with a STOP condition before the I2C has a chance to NACK transfer, and I2C_ENABLE[ENABLE] has been set to 0, then this bit is also set to 0x1. When read as 0x0, I2C is deemed to have been disabled without being actively involved in the data phase of a Slave-Receiver transfer. The CPU can safely read this bit when IC_EN is read as 0x0.
    0=Slave RX data is not lost; 1=Slave RX data is lost
  [1] SLV_DISABLED_WHILE_BUSY — Slave Disabled While Busy (Transmit, Receive). This bit indicates if a potential or active slave operation has been aborted due to the setting I2C_ENABLE[ENABLE] bit from 0x1 to 0x0. This bit is set when the CPU writes a 0x0 to the I2C_ENABLE register while: - I2C is receiving the address byte of the Slave-Transmitter operation from a remote master; - Address and data bytes of the Slave-Receiver operation from a remote master; When read as 0x1, I2C is deemed to have forced a NACK during any part of an I2C transfer, irrespective of whether the I2C address matches the slave address set in I2C (I2C_SAR register) OR if the transfer is completed before I2C_ENABLE is set to 0x0 but has not taken effect. If the remote I2C master terminates the transfer with a STOP condition before the I2C has a chance to NACK a transfer, and I2C_ENABLE[ENABLE] has been set to 0x0, then this bit will also be set to 0x1. When read as 0x0, I2C is deemed to have been disabled when there is master activity, or when the I2C bus is IDLE. The CPU can safely read this bit when IC_EN bit is read as 0x0.
    0=Slave is disabled when it is IDLE; 1=Slave is disabled when it is active
  [0] IC_EN — The CPU can safely read this bit anytime. When this bit is read as 0x0, the CPU can safely read SLV_RX_DATA_LOST bit and SLV_DISABLED_WHILE_BUSY bit.
    0=I2C is deemed completely inactive; 1=I2C is deemed to be in an enabled state
0xA0 I2C_FS_SPKLEN reset 0x5 — SS, FS or FM+ Spike Suppression Limit Register
  [7:0] IC_FS_SPKLEN — This field must be set before any I2C bus transaction can take place to ensure stable operation. This register sets the duration, measured in IC_CLK cycles, of the longest spike in the SCL or SDA lines that will be filtered out by the spike suppression logic. This register is written only when the I2C interface is disabled which corresponds to the I2C_ENABLE[ENABLE] register being set to 0x0. Writes at other times have no effect. The minimum valid value is 0x1.
0xAC I2C_SCL_STUCK_AT_LOW_TIMEOUT reset 0xFFFFFFFF — SCL Stuck at Low Timeout Register
  [31:0] IC_SCL_STUCK_LOW_TIMEOUT — I2C generates the interrupt to indicate SCL stuck at low (I2C_RAW_INTR_STAT[SCL_STUCK_AT_LOW]) if it detects the SCL stuck at low for the IC_SCL_STUCK_LOW_TIMEOUT in units of IC_CLK period. This field is written only when the I2C interface is disabled which corresponds to the I2C_ENABLE[ENABLE] register being set to 0x0. Writes at other timeshave no effect.
0xB0 I2C_SDA_STUCK_AT_LOW_TIMEOUT reset 0xFFFFFFFF — SDA Stuck at Low Timeout Register
  [31:0] IC_SDA_STUCK_LOW_TIMEOUT — I2C initiates the recovery of SDA line through enabling the I2C_ENABLE[SDA_STUCK_RECOVERY_EN] bit, if it detects the SDA stuck at low for the IC_SDA_STUCK_LOW_TIMEOUT in units of IC_CLK period.
0xB4 I2C_CLR_SCL_STUCK_DET ro — Clear SCL Stuck at Low Detect Interrupt Register
  [0] CLR_SCL_STUCK_DET — Read this register to clear the I2C_RAW_INTR_STAT[SCL_STUCK_AT_LOW] bit.
0xB8 I2C_DEVICE_ID ro — Device-ID Register
  [23:0] DEVICE_ID — Contains the Device-ID
0xF0 I2C_REG_TIMEOUT_RST reset 0x8 — Timeout Counter Reset Value Register
  [3:0] REG_TIMEOUT_RST_RW — This field holds reset value of REG_TIMEOUT counter register.
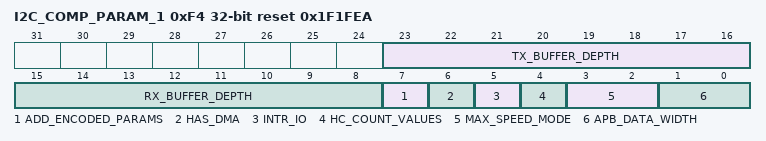
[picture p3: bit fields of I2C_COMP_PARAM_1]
0xF4 I2C_COMP_PARAM_1 ro reset 0x1F1FEA — Module Configuration Register 1
  [23:16] TX_BUFFER_DEPTH — The value of this field defines the TX buffer depth.
    31=32
  [15:8] RX_BUFFER_DEPTH — The value of this field defines the RX buffer depth.
    31=32
  [7] ADD_ENCODED_PARAMS — The value of this bit defines the Encoded parameters. Reading 1 in this bit means that the capabilityof reading these encoded parameters via software has beenincluded.
    1=Enables capability of reading encoded parameters
  [6] HAS_DMA — The value of this bit defines the DMA handshaking.
    1=DMA handshaking signals are enabled
  [5] INTR_IO — The value of this bit defines the interrupt outputs type.
    1=Combined interrupt outputs
  [4] HC_COUNT_VALUES — The value of this bit defines the count values.
    0=Programmable count values for each mode
  [3:2] MAX_SPEED_MODE — The value of this field defines the maximum speed mode.
    2=Fast
  [1:0] APB_DATA_WIDTH — The value of this field defines the APB data bus width.
    2=APB data bus width is 32 bits
0xF8 I2C_COMP_VERSION ro reset 0x3230322A — Component Version Register
  [31:0] IC_COMP_VERSION — Module component version
0xFC I2C_COMP_TYPE ro reset 0x44570140 — Component Type Register
  [31:0] IC_COMP_TYPE — Component type
